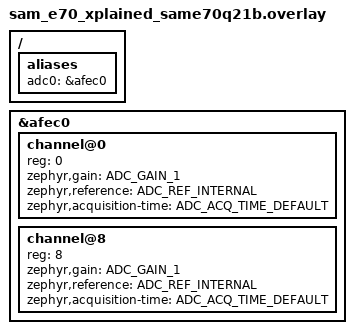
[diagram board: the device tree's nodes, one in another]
/*
 * Copyright (c) 2024 Centro de Inovacao EDGE
 *
 * SPDX-License-Identifier: Apache-2.0
 */

/ {
	aliases {
		adc0 = &afec0;
	};
};

&afec0 {
	#address-cells = <1>;
	#size-cells = <0>;

	channel@0 {
		reg = <0>;
		zephyr,gain = "ADC_GAIN_1";
		zephyr,reference = "ADC_REF_INTERNAL";
		zephyr,acquisition-time = <ADC_ACQ_TIME_DEFAULT>;
	};

	channel@8 {
		reg = <8>;
		zephyr,gain = "ADC_GAIN_1";
		zephyr,reference = "ADC_REF_INTERNAL";
		zephyr,acquisition-time = <ADC_ACQ_TIME_DEFAULT>;
	};
};
